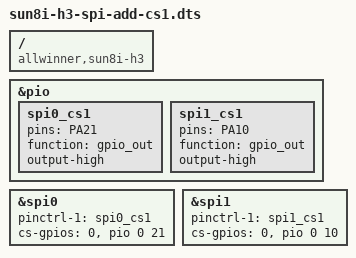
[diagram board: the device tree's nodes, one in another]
/dts-v1/;
/plugin/;

/ {
	compatible = "allwinner,sun8i-h3";
};

&pio {
	spi0_cs1: spi0_cs1 {
		pins = "PA21";
		function = "gpio_out";
		output-high;
	};

	spi1_cs1: spi1_cs1 {
		pins = "PA10";
		function = "gpio_out";
		output-high;
	};
};

&spi0 {
	pinctrl-names = "default", "default";
	pinctrl-1 = <&spi0_cs1>;
	cs-gpios = <0>, <&pio 0 21 0>; /* PA21 */
};

&spi1 {
	pinctrl-names = "default", "default";
	pinctrl-1 = <&spi1_cs1>;
	cs-gpios = <0>, <&pio 0 10 0>; /* PA10 */
};
